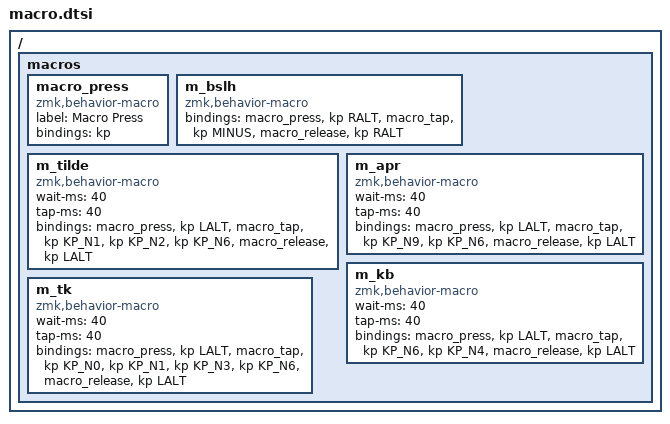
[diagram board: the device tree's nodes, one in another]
/{
macros {
    macro_press: macro_press {
      compatible = "zmk,behavior-macro";
      label = "Macro Press";
      #binding-cells = <2>;
      bindings = <&kp>;
    };
    m_bslh: m_bslh {
        compatible = "zmk,behavior-macro";
        #binding-cells = <0>;
        bindings
            = <&macro_press &kp RALT>
            , <&macro_tap &kp MINUS>
            , <&macro_release &kp RALT>
            ;
    };
    m_tilde: m_tilde {
        compatible = "zmk,behavior-macro";
        #binding-cells = <0>;
        wait-ms = <40>;
        tap-ms = <40>;
        bindings
            = <&macro_press &kp LALT>
            , <&macro_tap &kp KP_N1 &kp KP_N2 &kp KP_N6>
            , <&macro_release &kp LALT>
            ;
    };
    m_apr: m_apr {
        compatible = "zmk,behavior-macro";
        #binding-cells = <0>;
        wait-ms = <40>;
        tap-ms = <40>;
        bindings
            = <&macro_press &kp LALT>
            , <&macro_tap &kp KP_N9 &kp KP_N6>
            , <&macro_release &kp LALT>
            ;
    };
    m_kb: m_kb {
        compatible = "zmk,behavior-macro";
        #binding-cells = <0>;
        wait-ms = <40>;
        tap-ms = <40>;
        bindings
            = <&macro_press &kp LALT>
            , <&macro_tap &kp KP_N6 &kp KP_N4>
            , <&macro_release &kp LALT>
            ;
    };
    m_tk: m_tk {
        compatible = "zmk,behavior-macro";
        #binding-cells = <0>;
        wait-ms = <40>;
        tap-ms = <40>;
        bindings
            = <&macro_press &kp LALT>
            , <&macro_tap &kp KP_N0 &kp KP_N1 &kp KP_N3 &kp KP_N6>
            , <&macro_release &kp LALT>
            ;
    };
};
};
